# ESP32-C2 register map
Vendor: ESPRESSIF SYSTEMS (SHANGHAI) CO., LTD.; Series: ESP32 C-Series; File version: 11
CPU: RV32IMC r0p0, little endian, no MPU, no FPU, 0 interrupt priority bits
Address unit: 32 bits
Registers are 32-bit, read-write, reset 0x0 unless marked. A register's access mark holds for its fields unless they carry their own. Offsets are from the block's base; [hi:lo] are bit positions; {n}, {i} and the like mark numbered series.

## APB_SARADC — SAR (Successive Approximation Register) Analog-to-Digital Converter
Base 0x60040000
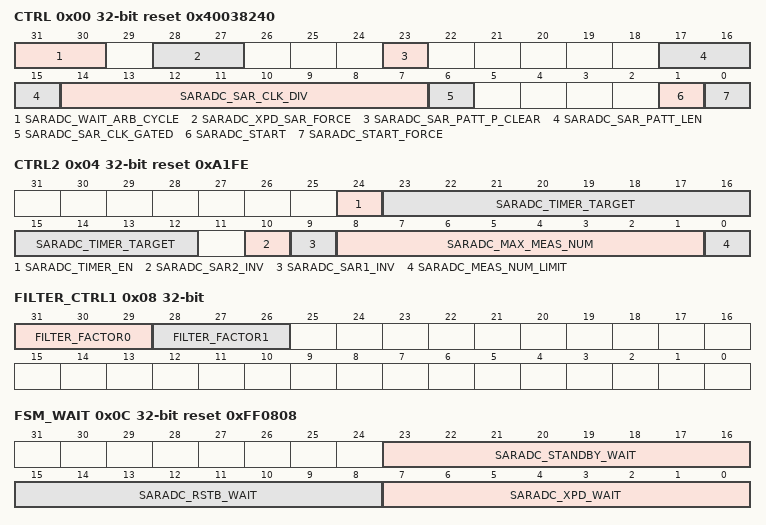
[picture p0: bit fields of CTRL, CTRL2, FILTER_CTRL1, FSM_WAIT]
0x00 CTRL reset 0x40038240 — register description
  [31:30] SARADC_WAIT_ARB_CYCLE — wait arbit signal stable after sar_done
  [28:27] SARADC_XPD_SAR_FORCE — force option to xpd sar blocks
  [23] SARADC_SAR_PATT_P_CLEAR — clear the pointer of pattern table for DIG ADC1 CTRL
  [17:15] SARADC_SAR_PATT_LEN — 0 ~ 15 means length 1 ~ 16
  [14:7] SARADC_SAR_CLK_DIV — SAR clock divider
  [6] SARADC_SAR_CLK_GATED — Need add description
  [1] SARADC_START — Need add description
  [0] SARADC_START_FORCE — Need add description
0x04 CTRL2 reset 0xA1FE — register description
  [24] SARADC_TIMER_EN — to enable saradc timer trigger
  [23:12] SARADC_TIMER_TARGET — to set saradc timer target
  [10] SARADC_SAR2_INV — 1: data to DIG ADC2 CTRL is inverted, otherwise not
  [9] SARADC_SAR1_INV — 1: data to DIG ADC1 CTRL is inverted, otherwise not
  [8:1] SARADC_MAX_MEAS_NUM — max conversion number
  [0] SARADC_MEAS_NUM_LIMIT — Need add description
0x08 FILTER_CTRL1 — register description
  [31:29] FILTER_FACTOR0 — Need add description
  [28:26] FILTER_FACTOR1 — Need add description
0x0C FSM_WAIT reset 0xFF0808 — register description
  [23:16] SARADC_STANDBY_WAIT — Need add description
  [15:8] SARADC_RSTB_WAIT — Need add description
  [7:0] SARADC_XPD_WAIT — Need add description
0x10 SAR1_STATUS ro — register description
  [31:0] SARADC_SAR1_STATUS — Need add description
0x14 SAR2_STATUS ro — register description
  [31:0] SARADC_SAR2_STATUS — Need add description
0x18 SAR_PATT_TAB1 reset 0xFFFFFF — register description
  [23:0] SARADC_SAR_PATT_TAB1 — item 0 ~ 3 for pattern table 1 (each item one byte)
0x1C SAR_PATT_TAB2 reset 0xFFFFFF — register description
  [23:0] SARADC_SAR_PATT_TAB2 — Item 4 ~ 7 for pattern table 1 (each item one byte)
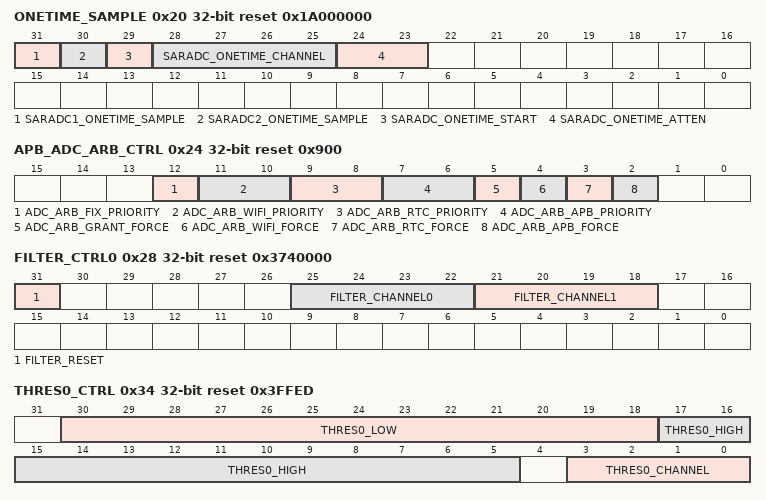
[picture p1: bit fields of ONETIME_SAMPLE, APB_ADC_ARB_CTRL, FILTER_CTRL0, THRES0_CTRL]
0x20 ONETIME_SAMPLE reset 0x1A000000 — register description
  [31] SARADC1_ONETIME_SAMPLE — Need add description
  [30] SARADC2_ONETIME_SAMPLE — Need add description
  [29] SARADC_ONETIME_START — Need add description
  [28:25] SARADC_ONETIME_CHANNEL — Need add description
  [24:23] SARADC_ONETIME_ATTEN — Need add description
0x24 APB_ADC_ARB_CTRL reset 0x900 — register description
  [12] ADC_ARB_FIX_PRIORITY — adc2 arbiter uses fixed priority
  [11:10] ADC_ARB_WIFI_PRIORITY — Set adc2 arbiter wifi priority
  [9:8] ADC_ARB_RTC_PRIORITY — Set adc2 arbiter rtc priority
  [7:6] ADC_ARB_APB_PRIORITY — Set adc2 arbiterapb priority
  [5] ADC_ARB_GRANT_FORCE — adc2 arbiter force grant
  [4] ADC_ARB_WIFI_FORCE — adc2 arbiter force to enable wifi controller
  [3] ADC_ARB_RTC_FORCE — adc2 arbiter force to enable rtc controller
  [2] ADC_ARB_APB_FORCE — adc2 arbiter force to enableapb controller
0x28 FILTER_CTRL0 reset 0x3740000 — register description
  [31] FILTER_RESET — enable apb_adc1_filter
  [25:22] FILTER_CHANNEL0 — apb_adc1_filter_factor
  [21:18] FILTER_CHANNEL1 — Need add description
0x2C APB_SARADC1_DATA_STATUS ro — register description
  [16:0] APB_SARADC1_DATA — Need add description
0x30 APB_SARADC2_DATA_STATUS ro — register description
  [16:0] APB_SARADC2_DATA — Need add description
0x34 THRES0_CTRL reset 0x3FFED — register description
  [30:18] THRES0_LOW — saradc1's thres0 monitor thres
  [17:5] THRES0_HIGH — saradc1's thres0 monitor thres
  [3:0] THRES0_CHANNEL — Need add description
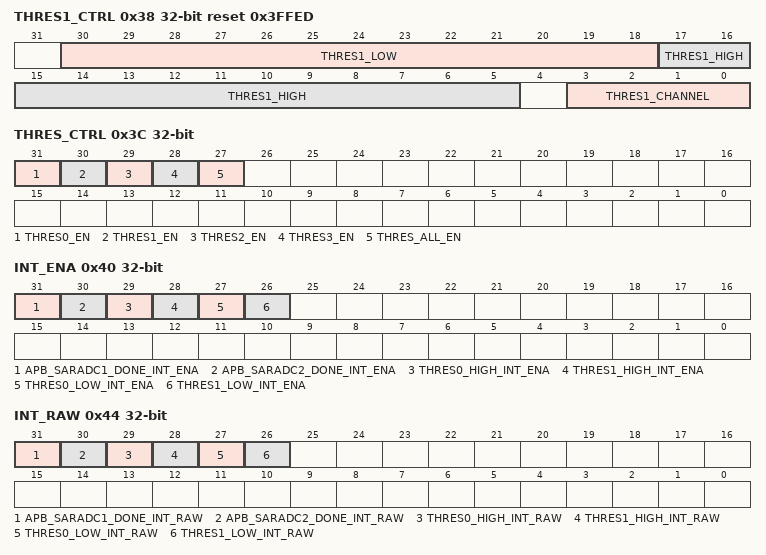
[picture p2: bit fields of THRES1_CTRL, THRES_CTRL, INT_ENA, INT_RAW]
0x38 THRES1_CTRL reset 0x3FFED — register description
  [30:18] THRES1_LOW — saradc1's thres0 monitor thres
  [17:5] THRES1_HIGH — saradc1's thres0 monitor thres
  [3:0] THRES1_CHANNEL — Need add description
0x3C THRES_CTRL — register description
  [31-n] THRES{n}_EN (n=0..3) — Need add description
  [27] THRES_ALL_EN — Need add description
0x40 INT_ENA — register description
  [31] APB_SARADC1_DONE_INT_ENA — Need add description
  [30] APB_SARADC2_DONE_INT_ENA — Need add description
  [29] THRES0_HIGH_INT_ENA — Need add description
  [28] THRES1_HIGH_INT_ENA — Need add description
  [27] THRES0_LOW_INT_ENA — Need add description
  [26] THRES1_LOW_INT_ENA — Need add description
0x44 INT_RAW ro — register description
  [31] APB_SARADC1_DONE_INT_RAW — Need add description
  [30] APB_SARADC2_DONE_INT_RAW — Need add description
  [29] THRES0_HIGH_INT_RAW — Need add description
  [28] THRES1_HIGH_INT_RAW — Need add description
  [27] THRES0_LOW_INT_RAW — Need add description
  [26] THRES1_LOW_INT_RAW — Need add description
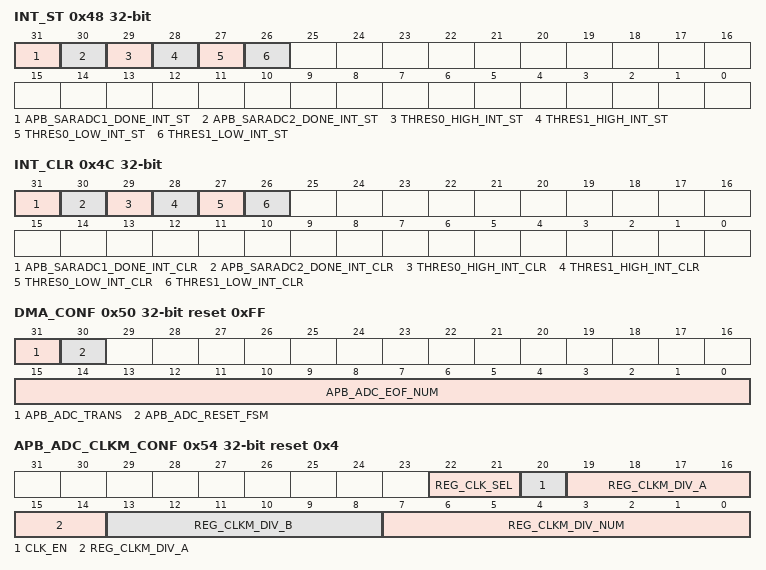
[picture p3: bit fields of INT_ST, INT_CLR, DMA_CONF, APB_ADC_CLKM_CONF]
0x48 INT_ST ro — register description
  [31] APB_SARADC1_DONE_INT_ST — Need add description
  [30] APB_SARADC2_DONE_INT_ST — Need add description
  [29] THRES0_HIGH_INT_ST — Need add description
  [28] THRES1_HIGH_INT_ST — Need add description
  [27] THRES0_LOW_INT_ST — Need add description
  [26] THRES1_LOW_INT_ST — Need add description
0x4C INT_CLR wo — register description
  [31] APB_SARADC1_DONE_INT_CLR — Need add description
  [30] APB_SARADC2_DONE_INT_CLR — Need add description
  [29] THRES0_HIGH_INT_CLR — Need add description
  [28] THRES1_HIGH_INT_CLR — Need add description
  [27] THRES0_LOW_INT_CLR — Need add description
  [26] THRES1_LOW_INT_CLR — Need add description
0x50 DMA_CONF reset 0xFF — register description
  [31] APB_ADC_TRANS — enable apb_adc use spi_dma
  [30] APB_ADC_RESET_FSM — reset_apb_adc_state
  [15:0] APB_ADC_EOF_NUM — the dma_in_suc_eof gen when sample cnt = spi_eof_num
0x54 APB_ADC_CLKM_CONF reset 0x4 — register description
  [22:21] REG_CLK_SEL — Set this bit to enable clk_apll
  [20] CLK_EN — Need add description
  [19:14] REG_CLKM_DIV_A — Fractional clock divider denominator value
  [13:8] REG_CLKM_DIV_B — Fractional clock divider numerator value
  [7:0] REG_CLKM_DIV_NUM — Integral I2S clock divider value
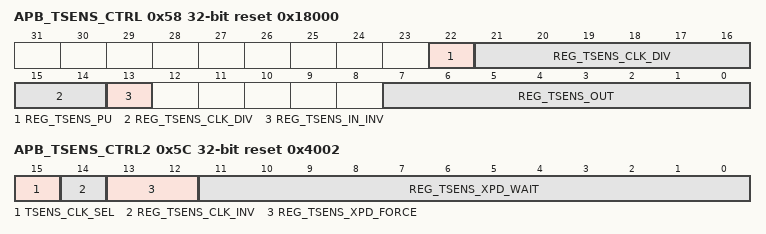
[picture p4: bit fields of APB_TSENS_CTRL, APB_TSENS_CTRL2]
0x58 APB_TSENS_CTRL access per field reset 0x18000 — register description
  [22] REG_TSENS_PU rw — Need add description
  [21:14] REG_TSENS_CLK_DIV rw — Need add description
  [13] REG_TSENS_IN_INV rw — Need add description
  [7:0] REG_TSENS_OUT ro — Need add description
0x5C APB_TSENS_CTRL2 reset 0x4002 — register description
  [15] TSENS_CLK_SEL — Need add description
  [14] REG_TSENS_CLK_INV — Need add description
  [13:12] REG_TSENS_XPD_FORCE — Need add description
  [11:0] REG_TSENS_XPD_WAIT — Need add description
0x60 CALI reset 0x8000 — register description
  [16:0] CFG — Need add description
0x3FC APB_CTRL_DATE reset 0x2107210 — register description
  [31:0] DATE — Need add description

## Notices in the file
Copyright 2025 Espressif Systems (Shanghai) PTE LTD
Licensed under the Apache License, Version 2.0 (the "License");
you may not use this file except in compliance with the License.
You may obtain a copy of the License at
http://www.apache.org/licenses/LICENSE-2.0
Unless required by applicable law or agreed to in writing, software
distributed under the License is distributed on an "AS IS" BASIS,
WITHOUT WARRANTIES OR CONDITIONS OF ANY KIND, either express or implied.
See the License for the specific language governing permissions and
limitations under the License.
